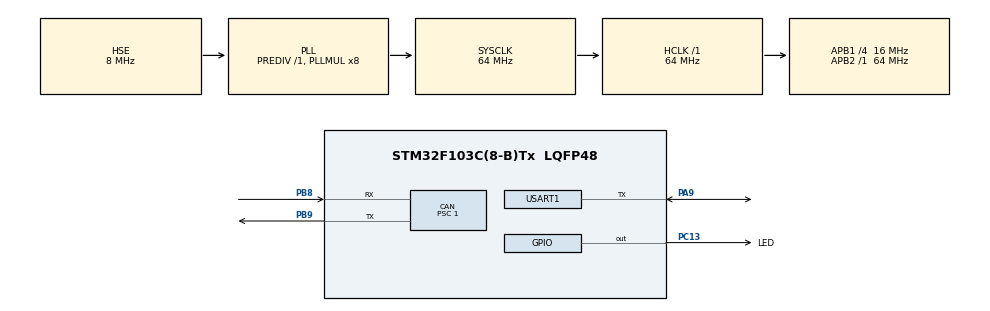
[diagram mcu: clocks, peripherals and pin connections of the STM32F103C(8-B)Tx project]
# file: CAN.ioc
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CAN.BS1=CAN_BS1_13TQ
CAN.BS2=CAN_BS2_2TQ
CAN.CalculateTimeBit=1000
CAN.CalculateTimeQuantum=62.5
CAN.Mode=CAN_MODE_SILENT_LOOPBACK
CAN.NART=ENABLE
CAN.Prescaler=1
IWDG.Prescaler=IWDG_PRESCALER_4
Mcu.Family=STM32F1
Mcu.Name=STM32F103C(8-B)Tx
Mcu.Package=LQFP48
NVIC.PriorityGroup=NVIC_PRIORITYGROUP_4
NVIC.USB_LP_CAN1_RX0_IRQn=true\:0\:0\:false\:false\:true\:true\:true
PA13.Mode=Serial_Wire
PA13.Signal=SYS_JTMS-SWDIO
PA14.Mode=Serial_Wire
PA14.Signal=SYS_JTCK-SWCLK
PA9.Mode=Half_duplex(single_wire_mode)
PA9.Signal=USART1_TX
PB8.Mode=Master
PB8.Signal=CAN_RX
PB9.Mode=Master
PB9.Signal=CAN_TX
PC13-TAMPER-RTC.GPIO_Label=LED
PC13-TAMPER-RTC.Signal=GPIO_Output
PD0-OSC_IN.Mode=HSE-External-Oscillator
PD0-OSC_IN.Signal=RCC_OSC_IN
PD1-OSC_OUT.Mode=HSE-External-Oscillator
PD1-OSC_OUT.Signal=RCC_OSC_OUT
ProjectManager.HeapSize=0x200
ProjectManager.StackSize=0x400
ProjectManager.TargetToolchain=STM32CubeIDE
RCC.AHBFreq_Value=64000000
RCC.APB1CLKDivider=RCC_HCLK_DIV4
RCC.APB1Freq_Value=16000000
RCC.APB1TimFreq_Value=32000000
RCC.APB2Freq_Value=64000000
RCC.APB2TimFreq_Value=64000000
RCC.HCLKFreq_Value=64000000
RCC.PLLMUL=RCC_PLL_MUL8
RCC.PLLSourceVirtual=RCC_PLLSOURCE_HSE
RCC.SYSCLKFreq_VALUE=64000000
RCC.SYSCLKSource=RCC_SYSCLKSOURCE_PLLCLK
RCC.USBFreq_Value=64000000
USART1.VirtualMode=VM_ASYNC
VP_IWDG_VS_IWDG.Mode=IWDG_Activate
board=custom

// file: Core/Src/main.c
/* USER CODE BEGIN Header */
/**
  ******************************************************************************
  * @file           : main.c
  * @brief          : Main program body
  ******************************************************************************
  * @attention
  *
  * <h2><center>&copy; Copyright (c) 2021 STMicroelectronics.
  * All rights reserved.</center></h2>
  *
  * This software component is licensed by ST under BSD 3-Clause license,
  * the "License"; You may not use this file except in compliance with the
  * License. You may obtain a copy of the License at:
  *                        opensource.org/licenses/BSD-3-Clause
  *
  ******************************************************************************
  */
/* USER CODE END Header */
#include "main.h"
#include "can.h"
#include "iwdg.h"
#include "usart.h"
#include "gpio.h"

/* USER CODE BEGIN Includes */
#include <stdio.h>
#include <stdint.h>
//#include "retarget.h"
/* USER CODE END Includes */

void SystemClock_Config(void);
/* USER CODE BEGIN PFP */
extern void initialise_monitor_handles(void);
/* USER CODE END PFP */

int main(void)
{
  /* USER CODE BEGIN 1 */
	//initialise_monitor_handles();
  /* USER CODE END 1 */

  /* MCU Configuration--------------------------------------------------------*/

  /* Reset of all peripherals, Initializes the Flash interface and the Systick. */
  HAL_Init();

  /* Configure the system clock */
  SystemClock_Config();

  /* Initialize all configured peripherals */
  MX_GPIO_Init();
  MX_CAN_Init();
  MX_USART1_UART_Init();
  MX_IWDG_Init();
  /* USER CODE BEGIN 2 */
  printf("Hello CAN from STM32\r\n\r\n");
  /* USER CODE END 2 */

  /* Infinite loop */
  /* USER CODE BEGIN WHILE */

  uint8_t rpm[] = {0x02, 0x01, 0x0D, 0x55, 0x55, 0x55, 0x55, 0x55};
  CAN_Send(0x7DF, rpm, sizeof(rpm)); // request RPM

  while (1)
  {
    /* USER CODE END WHILE */

    /* USER CODE BEGIN 3 */
	  HAL_IWDG_Refresh(&hiwdg);
	  HAL_Delay(100);
	  printf("$S<%lu\r\n", getRandInt(0, 250)); // simulate speed
//	  uint8_t *p = numTobytes(500);
//	  for (uint8_t i=1; i<*(p + 0); ++i) {
//		  printf("0x%02X ", *(p + i));
//	  }
//	  printf("\r\n");
  }
  /* USER CODE END 3 */
}

void SystemClock_Config(void)
{
  RCC_OscInitTypeDef RCC_OscInitStruct = {0};
  RCC_ClkInitTypeDef RCC_ClkInitStruct = {0};

  /** Initializes the RCC Oscillators according to the specified parameters
  * in the RCC_OscInitTypeDef structure.
  */
  RCC_OscInitStruct.OscillatorType = RCC_OSCILLATORTYPE_LSI|RCC_OSCILLATORTYPE_HSE;
  RCC_OscInitStruct.HSEState = RCC_HSE_ON;
  RCC_OscInitStruct.HSEPredivValue = RCC_HSE_PREDIV_DIV1;
  RCC_OscInitStruct.HSIState = RCC_HSI_ON;
  RCC_OscInitStruct.LSIState = RCC_LSI_ON;
  RCC_OscInitStruct.PLL.PLLState = RCC_PLL_ON;
  RCC_OscInitStruct.PLL.PLLSource = RCC_PLLSOURCE_HSE;
  RCC_OscInitStruct.PLL.PLLMUL = RCC_PLL_MUL8;
  if (HAL_RCC_OscConfig(&RCC_OscInitStruct) != HAL_OK)
  {
    Error_Handler();
  }
  /** Initializes the CPU, AHB and APB buses clocks
  */
  RCC_ClkInitStruct.ClockType = RCC_CLOCKTYPE_HCLK|RCC_CLOCKTYPE_SYSCLK
                              |RCC_CLOCKTYPE_PCLK1|RCC_CLOCKTYPE_PCLK2;
  RCC_ClkInitStruct.SYSCLKSource = RCC_SYSCLKSOURCE_PLLCLK;
  RCC_ClkInitStruct.AHBCLKDivider = RCC_SYSCLK_DIV1;
  RCC_ClkInitStruct.APB1CLKDivider = RCC_HCLK_DIV4;
  RCC_ClkInitStruct.APB2CLKDivider = RCC_HCLK_DIV1;

  if (HAL_RCC_ClockConfig(&RCC_ClkInitStruct, FLASH_LATENCY_2) != HAL_OK)
  {
    Error_Handler();
  }
}

void Error_Handler(void)
{
}

/************************ (C) COPYRIGHT STMicroelectronics *****END OF FILE****/
